# PY32F032xx register map
Vendor: Puya; Series: PY32F0; File version: 1.0.0
CPU: CM0+ r0p1, little endian, no MPU, no FPU, 4 interrupt priority bits
Registers are 32-bit, read-write, reset 0x0 unless marked. A register's access mark holds for its fields unless they carry their own. Offsets are from the block's base; [hi:lo] are bit positions.

## RCC — Reset and clock control
Base 0x40021000
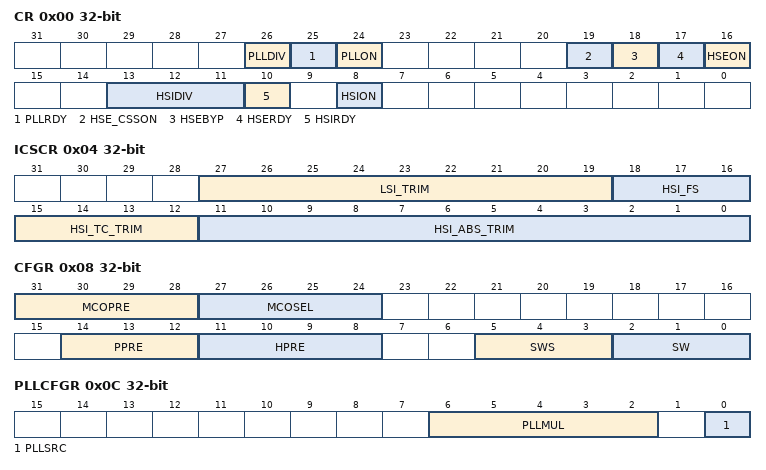
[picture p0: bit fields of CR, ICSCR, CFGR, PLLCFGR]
0x00 CR — Clock control register
  [26] PLLDIV
  [25] PLLRDY ro — PLL clock ready
  [24] PLLON — PLL clock enable
  [19] HSE_CSSON — HSE clock security system enabled
  [18] HSEBYP — HSE shields the crystal oscillator and selects the pin input clock
  [17] HSERDY ro — HSE crystal clock ready logo
  [16] HSEON — HSE crystal oscillator enabled
  [13:11] HSIDIV — HSI generates the crossover factor when HSISYS clocks
    1=0; 2=1; 4=2
  [10] HSIRDY ro — HSI clock ready logo
  [8] HSION — HSI clock enable bit
0x04 ICSCR — Internal clock sources calibrationregister
  [27:19] LSI_TRIM — Internal low-speed clock frequency calibration
  [18:16] HSI_FS — HSI frequency selection
    3=Freq24MHz (24 MHz HSI clock)
  [15:12] HSI_TC_TRIM — Clock frequency tc calibration value
  [11:0] HSI_ABS_TRIM — Clock frequency abs calibration value
0x08 CFGR — Clock configuration register
  [31:28] MCOPRE — Microprocessor output clock (MCO) divider factor
    1=0; 2=1; 4=2; 8=3
  [27:24] MCOSEL — MCO output clock selection
    1=0; 2=1; 4=2; 8=3
  [14:12] PPRE — APB clock division factor
    1=0; 2=1; 4=2
  [11:8] HPRE — The AHB clock HCLK is based on the crossover coefficient of SYSCLK
    1=0; 2=1; 4=2; 8=3
  [5:3] SWS — System clock source selection
    0=HSISYS (HSISYS used as system clock); 1=0; 1=HSE (HSE used as system clock); 2=1; 2=PLL (PLL used as system clock); 3=LSI (LSI used as system clock); 4=2; 4=LSE (LSE used as system clock)
  [2:0] SW — System clock source selection
    0=HSISYS (HSI selected as system clock); 1=0; 1=HSE (HSE selected as system clock); 2=1; 2=PLL; 3=LSI; 4=2; 4=LSE
0x0C PLLCFGR — PLL configuration register
  [6:2] PLLMUL
    1=0; 2=1; 4=2; 8=3; 16=4
  [0] PLLSRC
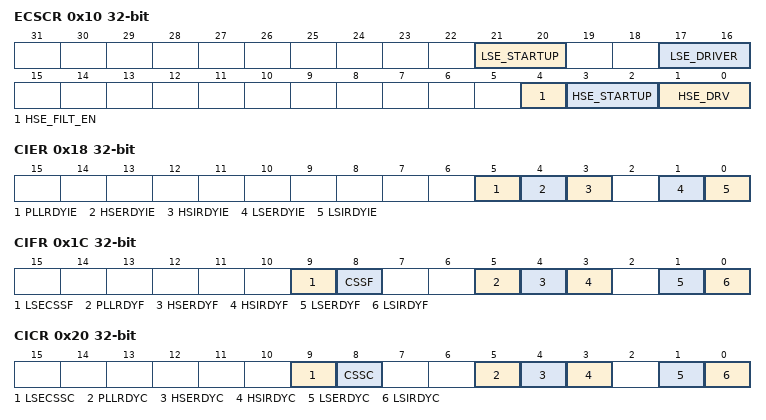
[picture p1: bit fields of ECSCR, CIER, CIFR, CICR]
0x10 ECSCR — External clock source control register
  [21:20] LSE_STARTUP — LSE crystal oscillator stabilization time selection
    1=0; 2=1
  [17:16] LSE_DRIVER — LSE drive capability setting
    1=0; 2=1
  [4] HSE_FILT_EN
  [3:2] HSE_STARTUP — HSE stabilization time selection
  [1:0] HSE_DRV — HSE drive capability setting
    1=0; 2=1
0x18 CIER — Clock interrupt enableregister
  [5] PLLRDYIE — PLL clock ready interrupt enabled
  [4] HSERDYIE — HSE clock ready interrupt enabled
  [3] HSIRDYIE — HSI clock ready interrupt enabled
  [1] LSERDYIE — LSE clock ready interrupt enabled
  [0] LSIRDYIE — LSI clock ready interrupt enabled
0x1C CIFR — Clock interrupt flag register
  [9] LSECSSF ro — LSE Clock Security System (CSS) interrupt flag
  [8] CSSF ro — HSE Clock Security System (CSS) interrupt flag
  [5] PLLRDYF ro — PLL clock ready interrupt flag
  [4] HSERDYF ro — HSE clock ready interrupt flag
  [3] HSIRDYF ro — HSI clock ready interrupt flag
  [1] LSERDYF ro — LSE clock ready interrupt flag
  [0] LSIRDYF ro — LSI clock ready interrupt flag
0x20 CICR — Clock interrupt clear register
  [9] LSECSSC — The LSE Clock Security System (CSS) interrupt flag is cleared
  [8] CSSC — The HSE Clock Security System (CSS) interrupt flag is cleared to zero
  [5] PLLRDYC — The PLL ready interrupt flag is cleared to zero
  [4] HSERDYC — The HSE ready interrupt flag is cleared to zero
  [3] HSIRDYC — The HSI ready interrupt flag is cleared to zero
  [1] LSERDYC — The LSE ready interrupt flag is cleared
  [0] LSIRDYC — The LSI ready interrupt flag is cleared
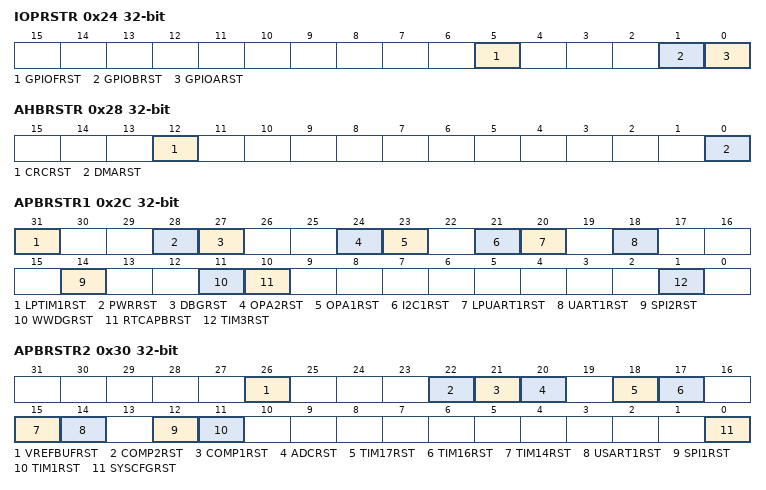
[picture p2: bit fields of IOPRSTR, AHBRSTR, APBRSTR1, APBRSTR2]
0x24 IOPRSTR — GPIO reset register
  [5] GPIOFRST — I/O PortF reset
  [1] GPIOBRST — I/O PortB reset
  [0] GPIOARST — I/O PortA reset
0x28 AHBRSTR — AHB peripheral reset register
  [12] CRCRST — The CRC module is reset
  [0] DMARST
0x2C APBRSTR1
  [31] LPTIM1RST
  [28] PWRRST — The Power interface module is reset.
  [27] DBGRST — The MCU Debug module is reset
  [24] OPA2RST — The OPA2 module is reset
  [23] OPA1RST — The OPA1 module is reset
  [21] I2C1RST — The I2C1 module is reset
  [20] LPUART1RST — The LPUART1 module is reset
  [18] UART1RST — The UART2 module is reset
  [14] SPI2RST
  [11] WWDGRST — The WWDG module is reset
  [10] RTCAPBRST — The RTC module APB is reset
  [1] TIM3RST — The Timer3 module APB is reset
0x30 APBRSTR2 — APB peripheral reset register2
  [26] VREFBUFRST
  [22] COMP2RST — The COMP2 module is reset
  [21] COMP1RST — The COMP1 module is reset
  [20] ADCRST — The ADC block is reset
  [18] TIM17RST — The TIM17 module is reset
  [17] TIM16RST — The TIM16 module is reset
  [15] TIM14RST — The TIM14 module is reset
  [14] USART1RST
  [12] SPI1RST — The SPI1 module is reset
  [11] TIM1RST — The TIM1 module is reset
  [0] SYSCFGRST — The SYSCFG module is reset
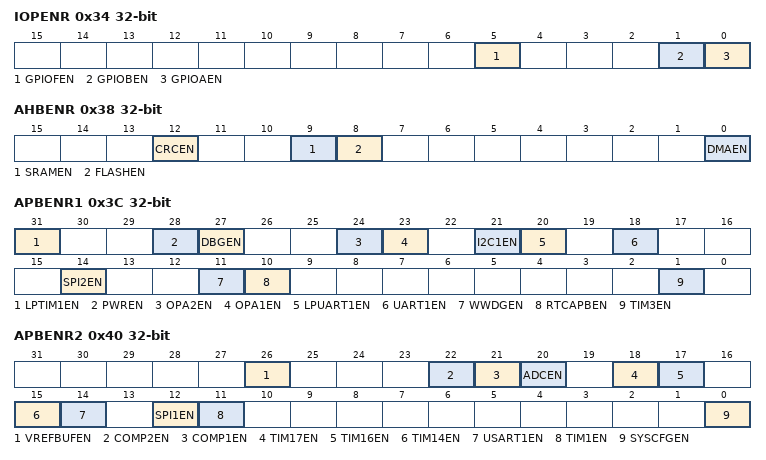
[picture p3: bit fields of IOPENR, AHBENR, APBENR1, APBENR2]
0x34 IOPENR — GPIO clock enable register
  [5] GPIOFEN — I/O PortF clock enable
  [1] GPIOBEN — I/O PortB clock enable
  [0] GPIOAEN — I/O PortA clock enable
0x38 AHBENR — AHB peripheral clock enableregister
  [12] CRCEN — CRC module clock enabled
  [9] SRAMEN
  [8] FLASHEN
  [0] DMAEN — DMA module clock enabled
0x3C APBENR1 — APB peripheral clock enable register1
  [31] LPTIM1EN
  [28] PWREN — The Power interface module clock enables
  [27] DBGEN — MCU Debug module clock enable
  [24] OPA2EN
  [23] OPA1EN
  [21] I2C1EN — I2C1 module clock enable
  [20] LPUART1EN
  [18] UART1EN — The UART1 module clock is enabled
  [14] SPI2EN
  [11] WWDGEN
  [10] RTCAPBEN — The RTC module APB clock is enabled
  [1] TIM3EN
0x40 APBENR2 — APB peripheral clock enable register2
  [26] VREFBUFEN
  [22] COMP2EN — COMP2 module clock enabled
  [21] COMP1EN — COMP1 module clock enable
  [20] ADCEN — ADC block clock enabled
  [18] TIM17EN
  [17] TIM16EN
  [15] TIM14EN — TIM14 module clock enable
  [14] USART1EN
  [12] SPI1EN — The SPI1 module clock is enabled
  [11] TIM1EN — The TIM1 module clock is enabled
  [0] SYSCFGEN — The SYSCFG module clock is enabled
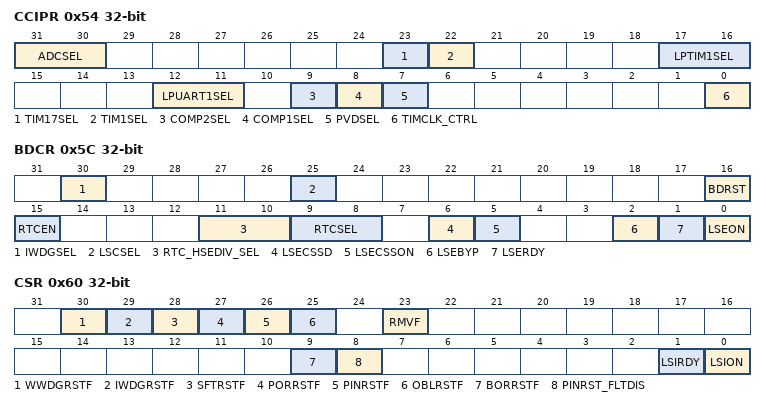
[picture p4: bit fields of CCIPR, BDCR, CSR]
0x54 CCIPR — Peripherals independent clock configurationregister
  [31:30] ADCSEL
    1=0; 2=1
  [23] TIM17SEL
  [22] TIM1SEL
  [17:16] LPTIM1SEL
    1=0; 2=1
  [12:11] LPUART1SEL
    1=0; 2=1
  [9] COMP2SEL — COMP2 module clock source selection
  [8] COMP1SEL — COMP1 module clock source selection
  [7] PVDSEL
  [0] TIMCLK_CTRL — TIMER PCLK FREQUENCY CONTROL
0x5C BDCR — RTC domain control register
  [30] IWDGSEL
  [25] LSCSEL — Low-speed clock selection
  [16] BDRST — RTC soft reset
  [15] RTCEN — RTC clock enabled
  [11:10] RTC_HSEDIV_SEL — The RTC clock source is selected as the division of the HSE clock
    1=0; 2=1
  [9:8] RTCSEL — RTC clock source selection
    1=0; 2=1
  [6] LSECSSD — LSE CSS (clock security system) detection failed
  [5] LSECSSON — LSE CSS enables
  [2] LSEBYP — LSE OSC bypass
  [1] LSERDY — LSE OSC ready
  [0] LSEON — LSE OSC enabled
0x60 CSR — Control/status register
  [30] WWDGRSTF ro
  [29] IWDGRSTF ro — IWDG reset flag
  [28] SFTRSTF ro — Soft reset flag
  [27] PORRSTF ro — POR reset flag
  [26] PINRSTF ro — External NRST pin reset flag
  [25] OBLRSTF ro — Option byte loader reset flag
  [23] RMVF — Clear the reset flag
  [9] BORRSTF ro — BOR reset flag
  [8] PINRST_FLTDIS — NRST filtering is prohibited
  [1] LSIRDY ro — LSI OSC stability flag
  [0] LSION — LSI OSC enabled
